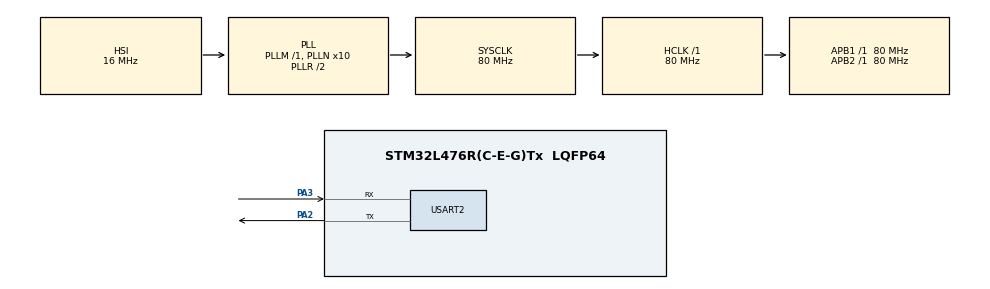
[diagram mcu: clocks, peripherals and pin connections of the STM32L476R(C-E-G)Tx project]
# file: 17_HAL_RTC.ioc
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Mcu.Family=STM32L4
Mcu.Name=STM32L476R(C-E-G)Tx
Mcu.Package=LQFP64
NVIC.PriorityGroup=NVIC_PRIORITYGROUP_4
PA13\ (JTMS-SWDIO).GPIO_Label=TMS
PA13\ (JTMS-SWDIO).Mode=Serial_Wire
PA13\ (JTMS-SWDIO).Signal=SYS_JTMS-SWDIO
PA14\ (JTCK-SWCLK).GPIO_Label=TCK
PA14\ (JTCK-SWCLK).Mode=Serial_Wire
PA14\ (JTCK-SWCLK).Signal=SYS_JTCK-SWCLK
PA2.Mode=Asynchronous
PA2.Signal=USART2_TX
PA3.Mode=Asynchronous
PA3.Signal=USART2_RX
PB3\ (JTDO-TRACESWO).GPIO_Label=SWO
PB3\ (JTDO-TRACESWO).Signal=SYS_JTDO-SWO
ProjectManager.HeapSize=0x200
ProjectManager.StackSize=0x400
ProjectManager.TargetToolchain=STM32CubeIDE
RCC.ADCFreq_Value=64000000
RCC.AHBFreq_Value=80000000
RCC.APB1Freq_Value=80000000
RCC.APB1TimFreq_Value=80000000
RCC.APB2Freq_Value=80000000
RCC.APB2TimFreq_Value=80000000
RCC.CortexFreq_Value=80000000
RCC.HCLKFreq_Value=80000000
RCC.HSE_VALUE=8000000
RCC.HSI_VALUE=16000000
RCC.LSE_VALUE=32768
RCC.MSI_VALUE=4000000
RCC.PLLN=10
RCC.PLLSourceVirtual=RCC_PLLSOURCE_HSI
RCC.PREFETCH_ENABLE=1
RCC.SYSCLKFreq_VALUE=80000000
RCC.SYSCLKSource=RCC_SYSCLKSOURCE_PLLCLK
RCC.USBFreq_Value=64000000
RCC.VCOOutputFreq_Value=160000000
USART2.VirtualMode-Asynchronous=VM_ASYNC
VP_RTC_VS_RTC_Activate.Mode=RTC_Enabled
VP_RTC_VS_RTC_Calendar.Mode=RTC_Calendar
board=NUCLEO-L476RG

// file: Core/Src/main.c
/* USER CODE BEGIN Header */
/**
  ******************************************************************************
  * @file           : main.c
  * @brief          : Main program body
  ******************************************************************************
  * @attention
  *
  * Copyright (c) 2025 STMicroelectronics.
  * All rights reserved.
  *
  * This software is licensed under terms that can be found in the LICENSE file
  * in the root directory of this software component.
  * If no LICENSE file comes with this software, it is provided AS-IS.
  *
  ******************************************************************************
  */
/* USER CODE END Header */
#include "main.h"
#include<stdio.h>

RTC_HandleTypeDef hrtc;

UART_HandleTypeDef huart2;

void SystemClock_Config(void);
static void MX_GPIO_Init(void);
static void MX_USART2_UART_Init(void);
static void MX_RTC_Init(void);
/* USER CODE BEGIN PFP */
void mymain(void);
/* USER CODE END PFP */

int main(void)
{

  /* USER CODE BEGIN 1 */
	//my_main();
  /* USER CODE END 1 */

  /* MCU Configuration--------------------------------------------------------*/

  /* Reset of all peripherals, Initializes the Flash interface and the Systick. */
	initialise_monitor_handles();
  HAL_Init();

  /* Configure the system clock */
  SystemClock_Config();

  /* Initialize all configured peripherals */
  MX_GPIO_Init();
  MX_USART2_UART_Init();
  MX_RTC_Init();

  /* Infinite loop */
  /* USER CODE BEGIN WHILE */
  RTC_TimeTypeDef t;
     RTC_DateTypeDef d;
  while (1)
  {
    /* USER CODE END WHILE */

    /* USER CODE BEGIN 3 */
	if (HAL_RTC_GetTime(&hrtc, &t, RTC_FORMAT_BCD) != HAL_OK)
	{
	  Error_Handler();
	}
	if (HAL_RTC_GetDate(&hrtc, &d, RTC_FORMAT_BCD) != HAL_OK)
	{
	  Error_Handler();
	}
      printf("%d:%d:%d  %d-%x-%d\n",t.Hours,t.Minutes,t.Seconds,d.Date,d.Month,d.Year);
      HAL_Delay(1000);
  }
  /* USER CODE END 3 */
}

void SystemClock_Config(void)
{
  RCC_OscInitTypeDef RCC_OscInitStruct = {0};
  RCC_ClkInitTypeDef RCC_ClkInitStruct = {0};

  /** Configure the main internal regulator output voltage
  */
  if (HAL_PWREx_ControlVoltageScaling(PWR_REGULATOR_VOLTAGE_SCALE1) != HAL_OK)
  {
    Error_Handler();
  }

  /** Initializes the RCC Oscillators according to the specified parameters
  * in the RCC_OscInitTypeDef structure.
  */
  RCC_OscInitStruct.OscillatorType = RCC_OSCILLATORTYPE_HSI|RCC_OSCILLATORTYPE_LSI;
  RCC_OscInitStruct.HSIState = RCC_HSI_ON;
  RCC_OscInitStruct.HSICalibrationValue = RCC_HSICALIBRATION_DEFAULT;
  RCC_OscInitStruct.LSIState = RCC_LSI_ON;
  RCC_OscInitStruct.PLL.PLLState = RCC_PLL_ON;
  RCC_OscInitStruct.PLL.PLLSource = RCC_PLLSOURCE_HSI;
  RCC_OscInitStruct.PLL.PLLM = 1;
  RCC_OscInitStruct.PLL.PLLN = 10;
  RCC_OscInitStruct.PLL.PLLP = RCC_PLLP_DIV7;
  RCC_OscInitStruct.PLL.PLLQ = RCC_PLLQ_DIV2;
  RCC_OscInitStruct.PLL.PLLR = RCC_PLLR_DIV2;
  if (HAL_RCC_OscConfig(&RCC_OscInitStruct) != HAL_OK)
  {
    Error_Handler();
  }

  /** Initializes the CPU, AHB and APB buses clocks
  */
  RCC_ClkInitStruct.ClockType = RCC_CLOCKTYPE_HCLK|RCC_CLOCKTYPE_SYSCLK
                              |RCC_CLOCKTYPE_PCLK1|RCC_CLOCKTYPE_PCLK2;
  RCC_ClkInitStruct.SYSCLKSource = RCC_SYSCLKSOURCE_PLLCLK;
  RCC_ClkInitStruct.AHBCLKDivider = RCC_SYSCLK_DIV1;
  RCC_ClkInitStruct.APB1CLKDivider = RCC_HCLK_DIV1;
  RCC_ClkInitStruct.APB2CLKDivider = RCC_HCLK_DIV1;

  if (HAL_RCC_ClockConfig(&RCC_ClkInitStruct, FLASH_LATENCY_4) != HAL_OK)
  {
    Error_Handler();
  }
}

static void MX_RTC_Init(void)
{

  RTC_TimeTypeDef sTime = {0};
  RTC_DateTypeDef sDate = {0};

  /** Initialize RTC Only
  */
  hrtc.Instance = RTC;
  hrtc.Init.HourFormat = RTC_HOURFORMAT_24;
  hrtc.Init.AsynchPrediv = 127;
  hrtc.Init.SynchPrediv = 255;
  hrtc.Init.OutPut = RTC_OUTPUT_DISABLE;
  hrtc.Init.OutPutRemap = RTC_OUTPUT_REMAP_NONE;
  hrtc.Init.OutPutPolarity = RTC_OUTPUT_POLARITY_HIGH;
  hrtc.Init.OutPutType = RTC_OUTPUT_TYPE_OPENDRAIN;
  if (HAL_RTC_Init(&hrtc) != HAL_OK)
  {
    Error_Handler();
  }

  /** Initialize RTC and set the Time and Date
  */
  sTime.Hours = 16;
  sTime.Minutes = 52;
  sTime.Seconds = 0;
  sTime.DayLightSaving = RTC_DAYLIGHTSAVING_NONE;
  sTime.StoreOperation = RTC_STOREOPERATION_RESET;
  if (HAL_RTC_SetTime(&hrtc, &sTime, RTC_FORMAT_BCD) != HAL_OK)
  {
    Error_Handler();
  }
  sDate.WeekDay = RTC_WEEKDAY_TUESDAY;
  sDate.Month = RTC_MONTH_NOVEMBER;
  sDate.Date = 25;
  sDate.Year = 25;

  if (HAL_RTC_SetDate(&hrtc, &sDate, RTC_FORMAT_BCD) != HAL_OK)
  {
    Error_Handler();
  }

}

static void MX_USART2_UART_Init(void)
{

  huart2.Instance = USART2;
  huart2.Init.BaudRate = 115200;
  huart2.Init.WordLength = UART_WORDLENGTH_8B;
  huart2.Init.StopBits = UART_STOPBITS_1;
  huart2.Init.Parity = UART_PARITY_NONE;
  huart2.Init.Mode = UART_MODE_TX_RX;
  huart2.Init.HwFlowCtl = UART_HWCONTROL_NONE;
  huart2.Init.OverSampling = UART_OVERSAMPLING_16;
  huart2.Init.OneBitSampling = UART_ONE_BIT_SAMPLE_DISABLE;
  huart2.AdvancedInit.AdvFeatureInit = UART_ADVFEATURE_NO_INIT;
  if (HAL_UART_Init(&huart2) != HAL_OK)
  {
    Error_Handler();
  }

}

static void MX_GPIO_Init(void)
{

  /* GPIO Ports Clock Enable */
  __HAL_RCC_GPIOA_CLK_ENABLE();
  __HAL_RCC_GPIOB_CLK_ENABLE();

}

void Error_Handler(void)
{
  __disable_irq();
  while (1)
  {
  }
}
